# STM32H7B0x register map
File version: 1.3
CPU: CM7 r0p1, little endian, MPU, FPU, 4 interrupt priority bits
Registers are 32-bit, read-write, reset 0x0 unless marked. A register's access mark holds for its fields unless they carry their own. Offsets are from the block's base; [hi:lo] are bit positions; lines under a group give offsets from that group; {n}, {i} and the like mark numbered series; 'fields as' and 'values as' point back to an identical list.

## ADC1 — Analog to Digital Converter
Base 0x40022000
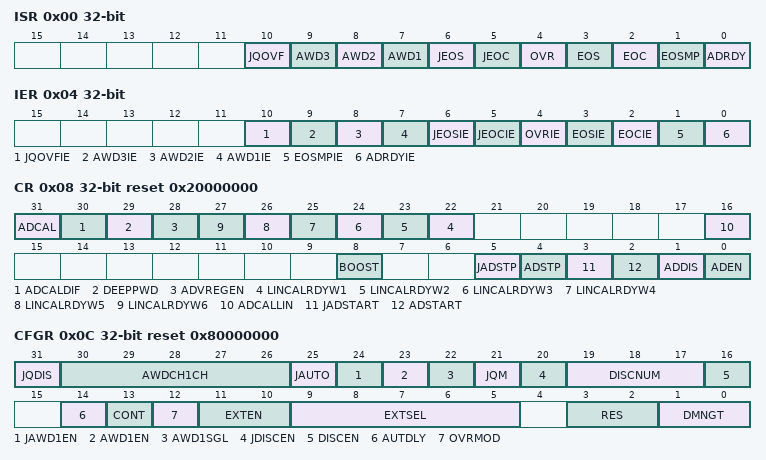
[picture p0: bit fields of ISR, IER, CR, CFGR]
0x00 ISR — ADC interrupt and status register
  [10] JQOVF — ADC group injected contexts queue overflow flag
  [9] AWD3 — ADC analog watchdog 3 flag
  [8] AWD2 — ADC analog watchdog 2 flag
  [7] AWD1 — ADC analog watchdog 1 flag
  [6] JEOS — ADC group injected end of sequence conversions flag
  [5] JEOC — ADC group injected end of unitary conversion flag
  [4] OVR — ADC group regular overrun flag
  [3] EOS — ADC group regular end of sequence conversions flag
  [2] EOC — ADC group regular end of unitary conversion flag
  [1] EOSMP — ADC group regular end of sampling flag
  [0] ADRDY — ADC ready flag
0x04 IER — ADC interrupt enable register
  [10] JQOVFIE — ADC group injected contexts queue overflow interrupt
  [9] AWD3IE — ADC analog watchdog 3 interrupt
  [8] AWD2IE — ADC analog watchdog 2 interrupt
  [7] AWD1IE — ADC analog watchdog 1 interrupt
  [6] JEOSIE — ADC group injected end of sequence conversions interrupt
  [5] JEOCIE — ADC group injected end of unitary conversion interrupt
  [4] OVRIE — ADC group regular overrun interrupt
  [3] EOSIE — ADC group regular end of sequence conversions interrupt
  [2] EOCIE — ADC group regular end of unitary conversion interrupt
  [1] EOSMPIE — ADC group regular end of sampling interrupt
  [0] ADRDYIE — ADC ready interrupt
0x08 CR reset 0x20000000 — ADC control register
  [31] ADCAL — ADC calibration
  [30] ADCALDIF — ADC differential mode for calibration
  [29] DEEPPWD — ADC deep power down enable
  [28] ADVREGEN — ADC voltage regulator enable
  [n+21] LINCALRDYW{n} (n=1..6) — Linearity calibration ready Word {n}
  [16] ADCALLIN — Linearity calibration
  [8] BOOST — Boost mode control
  [5] JADSTP — ADC group injected conversion stop
  [4] ADSTP — ADC group regular conversion stop
  [3] JADSTART — ADC group injected conversion start
  [2] ADSTART — ADC group regular conversion start
  [1] ADDIS — ADC disable
  [0] ADEN — ADC enable
0x0C CFGR reset 0x80000000 — ADC configuration register 1
  [31] JQDIS — ADC group injected contexts queue disable
  [30:26] AWDCH1CH — ADC analog watchdog 1 monitored channel selection
  [25] JAUTO — ADC group injected automatic trigger mode
  [24] JAWD1EN — ADC analog watchdog 1 enable on scope ADC group injected
  [23] AWD1EN — ADC analog watchdog 1 enable on scope ADC group regular
  [22] AWD1SGL — ADC analog watchdog 1 monitoring a single channel or all channels
  [21] JQM — ADC group injected contexts queue mode
  [20] JDISCEN — ADC group injected sequencer discontinuous mode
  [19:17] DISCNUM — ADC group regular sequencer discontinuous number of ranks
  [16] DISCEN — ADC group regular sequencer discontinuous mode
  [14] AUTDLY — ADC low power auto wait
  [13] CONT — ADC group regular continuous conversion mode
  [12] OVRMOD — ADC group regular overrun configuration
  [11:10] EXTEN — ADC group regular external trigger polarity
  [9:5] EXTSEL — ADC group regular external trigger source
  [3:2] RES — ADC data resolution
  [1:0] DMNGT — ADC DMA transfer enable
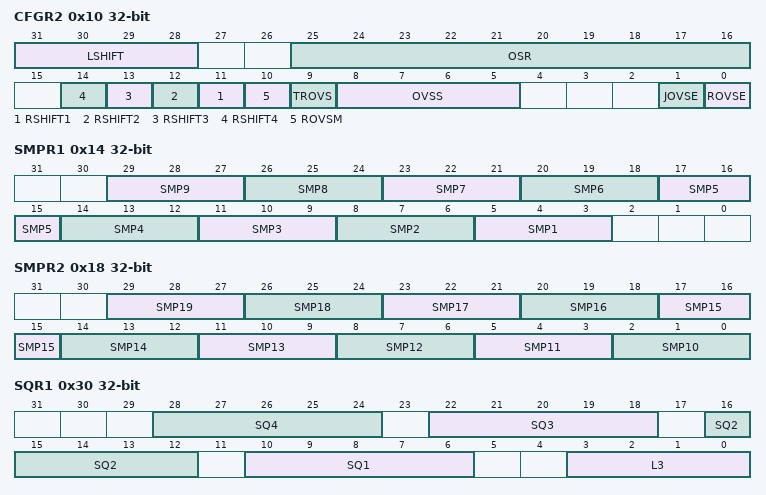
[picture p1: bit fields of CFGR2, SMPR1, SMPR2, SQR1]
0x10 CFGR2 — ADC configuration register 2
  [31:28] LSHIFT — Left shift factor
  [25:16] OSR — Oversampling ratio
  [n+10] RSHIFT{n} (n=1..4) — Right-shift data after Offset {n} correction
  [10] ROVSM — Regular Oversampling mode
  [9] TROVS — ADC oversampling discontinuous mode (triggered mode) for ADC group regular
  [8:5] OVSS — ADC oversampling shift
  [1] JOVSE — ADC oversampler enable on scope ADC group injected
  [0] ROVSE — ADC oversampler enable on scope ADC group regular
0x14 SMPR1 — ADC sampling time register 1
  [3n+2:3n] SMP{n} (n=1..9) — ADC channel {n} sampling time selection
0x18 SMPR2 — ADC sampling time register 2
  [29:27] SMP19 — ADC channel 18 sampling time selection
  [3n-28:3n-30] SMP{n} (n=10..18) — ADC channel {n} sampling time selection
0x1C PCSEL — ADC pre channel selection register
  [19:0] PCSEL — Channel x (VINP[i]) pre selection
0x20 LTR1 — ADC analog watchdog 1 threshold register
  [25:0] LTR1 — ADC analog watchdog 1 threshold low
0x24 LHTR1 reset 0x3FFFFFF — ADC analog watchdog 2 threshold register
  [25:0] LHTR1 — ADC analog watchdog 2 threshold low
0x30 SQR1 — ADC group regular sequencer ranks register 1
  [6n+4:6n] SQ{n} (n=1..4) — ADC group regular sequencer rank {n}
  [3:0] L3
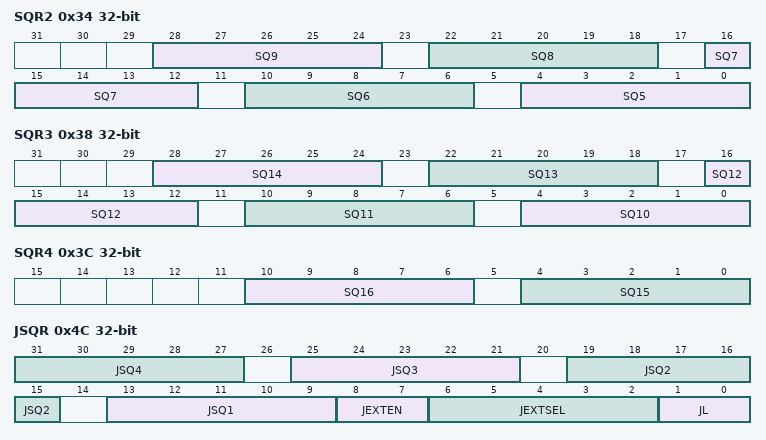
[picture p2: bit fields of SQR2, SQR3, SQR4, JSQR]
0x34 SQR2 — ADC group regular sequencer ranks register 2
  [6n-26:6n-30] SQ{n} (n=5..9) — ADC group regular sequencer rank {n}
0x38 SQR3 — ADC group regular sequencer ranks register 3
  [6n-56:6n-60] SQ{n} (n=10..14) — ADC group regular sequencer rank {n}
0x3C SQR4 — ADC group regular sequencer ranks register 4
  [10:6] SQ16 — ADC group regular sequencer rank 16
  [4:0] SQ15 — ADC group regular sequencer rank 15
0x40 DR ro — ADC group regular conversion data register
  [15:0] RDATA — ADC group regular conversion data
0x4C JSQR — ADC group injected sequencer register
  [6n+7:6n+3] JSQ{n} (n=1..4) — ADC group injected sequencer rank {n}
  [8:7] JEXTEN — ADC group injected external trigger polarity
  [6:2] JEXTSEL — ADC group injected external trigger source
  [1:0] JL — ADC group injected sequencer scan length
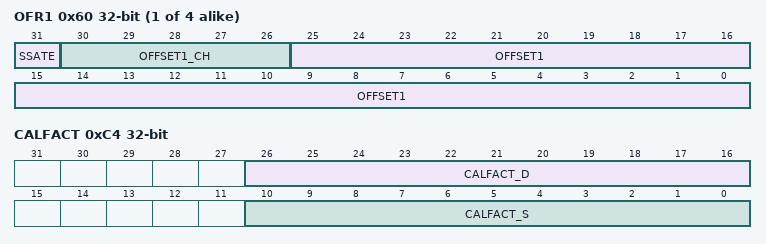
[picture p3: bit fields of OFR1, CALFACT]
{0x5C+4i} OFR{i} (i=1..4) — ADC offset number {i} register
  [31] SSATE — ADC offset number 1 enable
  [30:26] OFFSET1_CH — ADC offset number 1 channel selection
  [25:0] OFFSET1 — ADC offset number 1 offset level
{0x7C+4i} JDR{i} ro (i=1..4) — ADC group injected sequencer rank {i} register
  [31:0] JDATA{i} — ADC group injected sequencer rank {i} conversion data
0xA0 AWD2CR — ADC analog watchdog 2 configuration register
  [19:0] AWD2CH — ADC analog watchdog 2 monitored channel selection
0xA4 AWD3CR — ADC analog watchdog 3 configuration register
  [20:1] AWD3CH — ADC analog watchdog 3 monitored channel selection
0xB0 LTR2 — ADC watchdog lower threshold register 2
  [25:0] LTR2 — Analog watchdog 2 lower threshold
0xB4 HTR2 reset 0x3FFFFFF — ADC watchdog higher threshold register 2
  [25:0] HTR2 — Analog watchdog 2 higher threshold
0xB8 LTR3 — ADC watchdog lower threshold register 3
  [25:0] LTR3 — Analog watchdog 3 lower threshold
0xBC HTR3 reset 0x3FFFFFF — ADC watchdog higher threshold register 3
  [25:0] HTR3 — Analog watchdog 3 higher threshold
0xC0 DIFSEL — ADC channel differential or single-ended mode selection register
  [19:0] DIFSEL — ADC channel differential or single-ended mode for channel
0xC4 CALFACT — ADC calibration factors register
  [26:16] CALFACT_D — ADC calibration factor in differential mode
  [10:0] CALFACT_S — ADC calibration factor in single-ended mode
0xC8 CALFACT2 — ADC Calibration Factor register 2
  [29:0] LINCALFACT — Linearity Calibration Factor

## ADC2 — Analog to Digital Converter
Base 0x40022100
Registers as ADC1; these are added or differ:
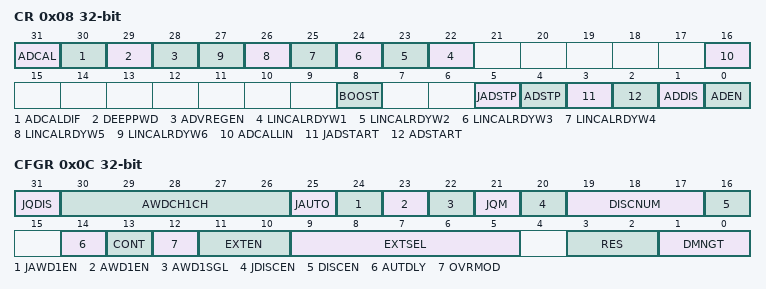
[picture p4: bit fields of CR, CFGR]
0x08 CR — ADC control register
  fields as ADC1.CR
0x0C CFGR — ADC configuration register 1
  fields as ADC1.CFGR
0x20 LTR1 reset 0xFFF0000 — ADC analog watchdog 1 threshold register
  [25:0] LTR1 — ADC analog watchdog 1 threshold low
0x24 LHTR1 reset 0xFFF0000 — ADC analog watchdog 2 threshold register
  [25:0] LHTR1 — ADC analog watchdog 2 threshold low
0xB4 HTR2 — ADC watchdog higher threshold register 2
  [25:0] HTR2 — Analog watchdog 2 higher threshold
0xBC HTR3 — ADC watchdog higher threshold register 3
  [25:0] HTR3 — Analog watchdog 3 higher threshold
